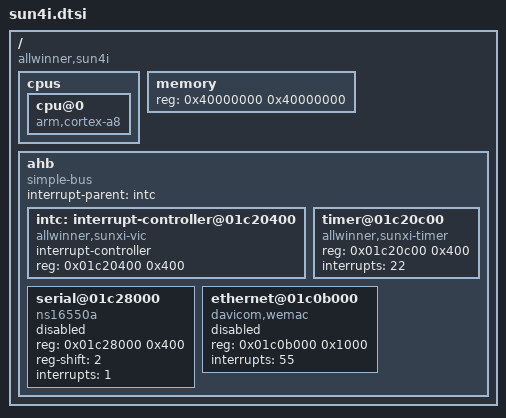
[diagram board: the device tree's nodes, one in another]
/*
 * Copyright 2012 Stefan Roese <sr@denx.de>
 *
 * The code contained herein is licensed under the GNU General Public
 * License. You may obtain a copy of the GNU General Public License
 * Version 2 or later at the following locations:
 *
 * http://www.opensource.org/licenses/gpl-license.html
 * http://www.gnu.org/copyleft/gpl.html
 */

/include/ "skeleton.dtsi"

/ {
	compatible = "allwinner,sun4i", "allwinner,sun5i";

	cpus {
		cpu@0 {
			compatible = "arm,cortex-a8";
		};
	};

	memory {
		device_type = "memory";
		reg = <0x40000000 0x40000000>;
	};

	ahb {
		#address-cells = <1>;
		#size-cells = <1>;
		compatible = "simple-bus";
		interrupt-parent = <&intc>;
		ranges = <0x00000000 0x00000000 0x02000000>;

		intc: interrupt-controller@01c20400 {
			compatible = "allwinner,sunxi-vic";
			interrupt-controller;
			reg = <0x01c20400 0x400>;
			#interrupt-cells = <1>;
		};

		timer@01c20c00 {
			compatible = "allwinner,sunxi-timer";
			reg = <0x01c20c00 0x400>;
			interrupts = <22>;
		};

		serial@01c28000 {
			compatible = "ns16550a";
			reg = <0x01c28000 0x400>;
			reg-shift = <2>;
			interrupts = <1>;
			status = "disabled";
		};

		ethernet@01c0b000 {
			compatible = "davicom,wemac";
			reg = <0x01c0b000 0x1000>;
			interrupts = <55>;
			status = "disabled";
		};
	};
};
